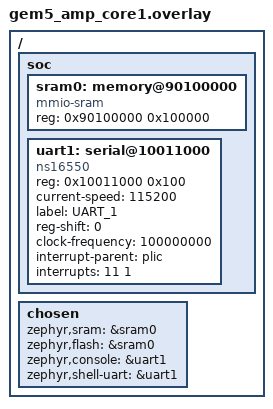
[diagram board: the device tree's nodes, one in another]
/ {
    soc {
        sram0: memory@90100000 {
            compatible = "mmio-sram";
            reg = <0x90100000 0x100000>;
        };
        
        uart1: serial@10011000 {
            compatible = "ns16550";
            reg = <0x10011000 0x100>;
            status = "okay";
            current-speed = <115200>;
            label = "UART_1";
            reg-shift = <0>;
            clock-frequency = <100000000>;
            interrupt-parent = <&plic>;
            interrupts = <11 1>;
        };
    };

    chosen {
        zephyr,sram = &sram0;
        zephyr,flash = &sram0;
        zephyr,console = &uart1;
        zephyr,shell-uart = &uart1;
    };
};



